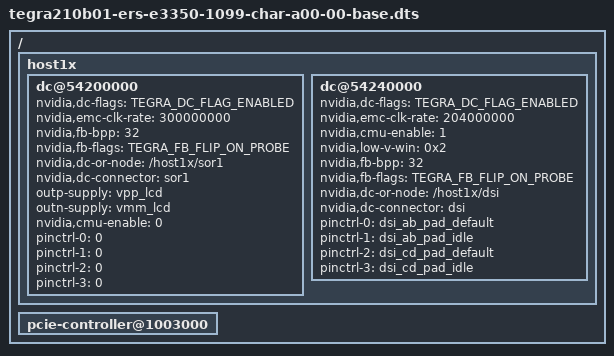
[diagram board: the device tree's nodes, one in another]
/*
 * Copyright (c) 2017, NVIDIA CORPORATION.  All rights reserved.
 *
 * This program is free software; you can redistribute it and/or modify
 * it under the terms of the GNU General Public License as published by
 * the Free Software Foundation; version 2 of the License.
 *
 * This program is distributed in the hope that it will be useful, but WITHOUT
 * ANY WARRANTY; without even the implied warranty of MERCHANTABILITY or
 * FITNESS FOR A PARTICULAR PURPOSE.  See the GNU General Public License for
 * more details.
 */

#include "tegra210b01-ers-e3350-1099-a00-00-base.dts"
/ {
	host1x {
		/* tegradc.0 */
		dc@54200000 {
			status = "okay";
			nvidia,dc-flags = <TEGRA_DC_FLAG_ENABLED>;
			nvidia,emc-clk-rate = <300000000>;
			nvidia,fb-bpp = <32>; /* bits per pixel */
			nvidia,fb-flags = <TEGRA_FB_FLIP_ON_PROBE>;
			nvidia,dc-or-node = "/host1x/sor1";
			nvidia,dc-connector = <&sor1>;
			outp-supply = <&vpp_lcd>;
			outn-supply = <&vmm_lcd>;
			nvidia,cmu-enable = <0>;
			pinctrl-names = "";
			pinctrl-0 = <0>;
			pinctrl-1 = <0>;
			pinctrl-2 = <0>;
			pinctrl-3 = <0>;
		};
		/* tegradc.1 */
		dc@54240000 {
			status = "okay";
			nvidia,dc-flags = <TEGRA_DC_FLAG_ENABLED>;
			nvidia,emc-clk-rate = <204000000>;
			nvidia,cmu-enable = <1>;
			nvidia,low-v-win = <0x2>;
			nvidia,fb-bpp = <32>; /* bits per pixel */
			nvidia,fb-flags = <TEGRA_FB_FLIP_ON_PROBE>;
			nvidia,dc-or-node = "/host1x/dsi";
			nvidia,dc-connector = <&dsi>;
			pinctrl-names = "pad_ab_default", "pad_ab_idle",
				"pad_cd_default", "pad_cd_idle";
			pinctrl-0 = <&dsi_ab_pad_default>;
			pinctrl-1 = <&dsi_ab_pad_idle>;
			pinctrl-2 = <&dsi_cd_pad_default>;
			pinctrl-3 = <&dsi_cd_pad_idle>;
		};
	};

	pcie-controller@1003000 {
		/delete-property/ nvidia,wake-gpio;
	};
};


